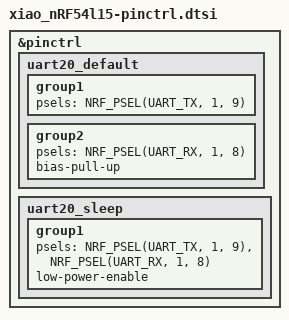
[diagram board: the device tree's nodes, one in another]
#include <zephyr/dt-bindings/pinctrl/nrf-pinctrl.h>

&pinctrl {
	uart20_default: uart20_default {
		group1 {
			psels = <NRF_PSEL(UART_TX, 1, 9)>;
		};
		group2 {
			psels = <NRF_PSEL(UART_RX, 1, 8)>;
			bias-pull-up;
		};
	};
	uart20_sleep: uart20_sleep {
		group1 {
			psels = <NRF_PSEL(UART_TX, 1, 9)>, <NRF_PSEL(UART_RX, 1, 8)>;
			low-power-enable;
		};
	};
};
